# ATmega1280 device description
Architecture: AVR8; Family: megaAVR
Registers are 8-bit, access not given, no defined reset value unless marked. A register's access mark holds for its fields unless they carry their own. Offsets are from the block's base; [hi:lo] are bit positions.

## WDT — Watchdog Timer
Instances: WDT 0x00
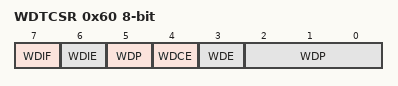
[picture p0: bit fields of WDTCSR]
0x60 WDTCSR — Watchdog Timer Control Register
  [7] WDIF — Watchdog Timeout Interrupt Flag
  [6] WDIE — Watchdog Timeout Interrupt Enable
  [4] WDCE — Watchdog Change Enable
  [3] WDE — Watch Dog Enable
  [5,2:0] WDP — Watchdog Timer Prescaler Bits
    0=Oscillator Cycles 2K; 1=Oscillator Cycles 4K; 2=Oscillator Cycles 8K; 3=Oscillator Cycles 16K; 4=Oscillator Cycles 32K; 5=Oscillator Cycles 64K; 6=Oscillator Cycles 128K; 7=Oscillator Cycles 256K; 8=Oscillator Cycles 512K; 9=Oscillator Cycles 1024K

## EEPROM
Instances: EEPROM 0x00
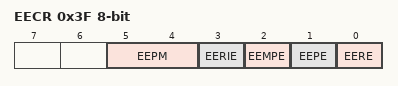
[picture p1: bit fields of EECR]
0x3F EECR — EEPROM Control Register
  [5:4] EEPM — EEPROM Programming Mode Bits
    0=Erase and Write in one operation; 1=Erase Only; 2=Write Only
  [3] EERIE — EEPROM Ready Interrupt Enable
  [2] EEMPE — EEPROM Master Write Enable
  [1] EEPE — EEPROM Write Enable
  [0] EERE — EEPROM Read Enable
0x40 EEDR — EEPROM Data Register
0x41 EEAR 16-bit bits used 11:0 — EEPROM Address Register Low Bytes

## TC5 (TC16 module) — Timer/Counter, 16-bit
Instances: TC5 0x00
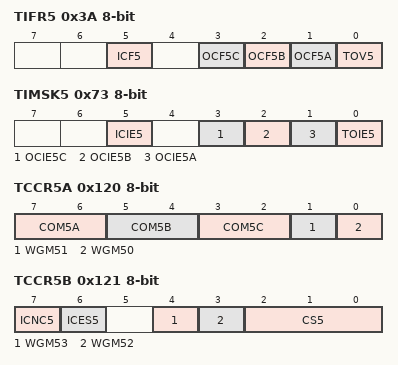
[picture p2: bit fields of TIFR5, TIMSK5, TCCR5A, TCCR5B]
0x3A TIFR5 — Timer/Counter5 Interrupt Flag register
  [5] ICF5 — Input Capture Flag 5
  [3] OCF5C — Output Compare Flag 5C
  [2] OCF5B — Output Compare Flag 5B
  [1] OCF5A — Output Compare Flag 5A
  [0] TOV5 — Timer/Counter5 Overflow Flag
0x73 TIMSK5 — Timer/Counter5 Interrupt Mask Register
  [5] ICIE5 — Timer/Counter5 Input Capture Interrupt Enable
  [3] OCIE5C — Timer/Counter5 Output Compare C Match Interrupt Enable
  [2] OCIE5B — Timer/Counter5 Output Compare B Match Interrupt Enable
  [1] OCIE5A — Timer/Counter5 Output Compare A Match Interrupt Enable
  [0] TOIE5 — Timer/Counter5 Overflow Interrupt Enable
0x120 TCCR5A — Timer/Counter5 Control Register A
  [7:6] COM5A — Compare Output Mode 1A, bits
  [5:4] COM5B — Compare Output Mode 5B, bits
  [3:2] COM5C — Compare Output Mode 5C, bits
  [1] WGM51 — Waveform Generation Mode
  [0] WGM50 — Waveform Generation Mode
0x121 TCCR5B — Timer/Counter5 Control Register B
  [7] ICNC5 — Input Capture 5 Noise Canceler
  [6] ICES5 — Input Capture 5 Edge Select
  [4] WGM53 (bit 2 of the value upward) — Waveform Generation Mode
  [3] WGM52 (bit 2 of the value upward) — Waveform Generation Mode
  [2:0] CS5 — Prescaler source of Timer/Counter 5
    0=No Clock Source (Stopped); 1=Running, No Prescaling; 2=Running, CLK/8; 3=Running, CLK/64; 4=Running, CLK/256; 5=Running, CLK/1024; 6=Running, ExtClk Tx Falling Edge; 7=Running, ExtClk Tx Rising Edge
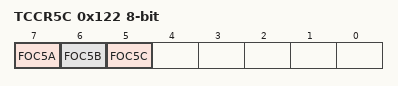
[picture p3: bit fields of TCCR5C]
0x122 TCCR5C — Timer/Counter 5 Control Register C
  [7] FOC5A — Force Output Compare 5A
  [6] FOC5B — Force Output Compare 5B
  [5] FOC5C — Force Output Compare 5C
0x124 TCNT5 16-bit — Timer/Counter5 Bytes
0x126 ICR5 16-bit — Timer/Counter5 Input Capture Register Bytes
0x128 OCR5A 16-bit — Timer/Counter5 Output Compare Register A Bytes
0x12A OCR5B 16-bit — Timer/Counter5 Output Compare Register B Bytes
0x12C OCR5C 16-bit — Timer/Counter5 Output Compare Register B Bytes

## TC4 (TC16 module) — Timer/Counter, 16-bit
Instances: TC4 0x00
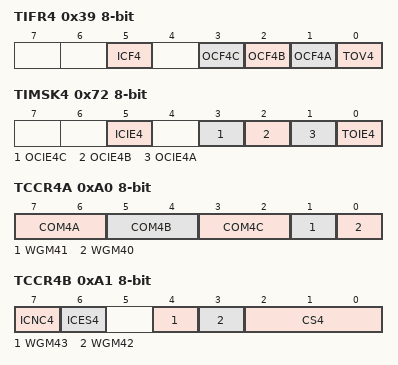
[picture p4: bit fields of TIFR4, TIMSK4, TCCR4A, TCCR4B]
0x39 TIFR4 — Timer/Counter4 Interrupt Flag register
  [5] ICF4 — Input Capture Flag 4
  [3] OCF4C — Output Compare Flag 4C
  [2] OCF4B — Output Compare Flag 4B
  [1] OCF4A — Output Compare Flag 4A
  [0] TOV4 — Timer/Counter4 Overflow Flag
0x72 TIMSK4 — Timer/Counter4 Interrupt Mask Register
  [5] ICIE4 — Timer/Counter4 Input Capture Interrupt Enable
  [3] OCIE4C — Timer/Counter4 Output Compare C Match Interrupt Enable
  [2] OCIE4B — Timer/Counter4 Output Compare B Match Interrupt Enable
  [1] OCIE4A — Timer/Counter4 Output Compare A Match Interrupt Enable
  [0] TOIE4 — Timer/Counter4 Overflow Interrupt Enable
0xA0 TCCR4A — Timer/Counter4 Control Register A
  [7:6] COM4A — Compare Output Mode 1A, bits
  [5:4] COM4B — Compare Output Mode 4B, bits
  [3:2] COM4C — Compare Output Mode 4C, bits
  [1] WGM41 — Waveform Generation Mode
  [0] WGM40 — Waveform Generation Mode
0xA1 TCCR4B — Timer/Counter4 Control Register B
  [7] ICNC4 — Input Capture 4 Noise Canceler
  [6] ICES4 — Input Capture 4 Edge Select
  [4] WGM43 (bit 2 of the value upward) — Waveform Generation Mode
  [3] WGM42 (bit 2 of the value upward) — Waveform Generation Mode
  [2:0] CS4 — Prescaler source of Timer/Counter 4
    0=No Clock Source (Stopped); 1=Running, No Prescaling; 2=Running, CLK/8; 3=Running, CLK/64; 4=Running, CLK/256; 5=Running, CLK/1024; 6=Running, ExtClk Tx Falling Edge; 7=Running, ExtClk Tx Rising Edge
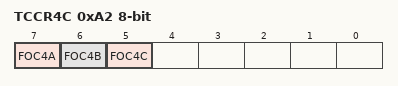
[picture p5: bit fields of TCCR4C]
0xA2 TCCR4C — Timer/Counter 4 Control Register C
  [7] FOC4A — Force Output Compare 4A
  [6] FOC4B — Force Output Compare 4B
  [5] FOC4C — Force Output Compare 4C
0xA4 TCNT4 16-bit — Timer/Counter4 Bytes
0xA6 ICR4 16-bit — Timer/Counter4 Input Capture Register Bytes
0xA8 OCR4A 16-bit — Timer/Counter4 Output Compare Register A Bytes
0xAA OCR4B 16-bit — Timer/Counter4 Output Compare Register B Bytes
0xAC OCR4C 16-bit — Timer/Counter4 Output Compare Register B Bytes
